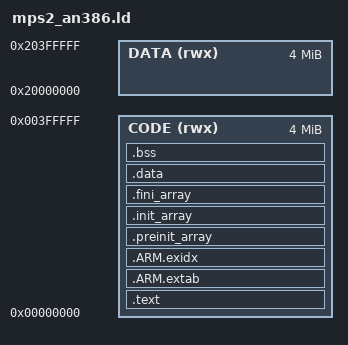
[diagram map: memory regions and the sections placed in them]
/* Linker script for tests in QEMU mps2-an386 (Cortex-M4F): everything in the 4 MB
   code RAM at 0x0, stack at the top of the data RAM. */
MEMORY { CODE (rwx) : ORIGIN = 0x00000000, LENGTH = 4M
         DATA (rwx) : ORIGIN = 0x20000000, LENGTH = 4M }
ENTRY(Reset_Handler)
SECTIONS {
  .text : { KEEP(*(.vectors)) *(.text*) *(.rodata*) KEEP(*(.init)) KEEP(*(.fini)) } > CODE
  .ARM.extab : { *(.ARM.extab* .gnu.linkonce.armextab.*) } > CODE
  .ARM.exidx : { __exidx_start = .; *(.ARM.exidx* .gnu.linkonce.armexidx.*) __exidx_end = .; } > CODE
  .preinit_array : { PROVIDE_HIDDEN(__preinit_array_start = .); KEEP(*(.preinit_array*)) PROVIDE_HIDDEN(__preinit_array_end = .); } > CODE
  .init_array : { PROVIDE_HIDDEN(__init_array_start = .); KEEP(*(SORT(.init_array.*))) KEEP(*(.init_array*)) PROVIDE_HIDDEN(__init_array_end = .); } > CODE
  .fini_array : { PROVIDE_HIDDEN(__fini_array_start = .); KEEP(*(SORT(.fini_array.*))) KEEP(*(.fini_array*)) PROVIDE_HIDDEN(__fini_array_end = .); } > CODE
  .data : { *(.data*) } > CODE
  .bss (NOLOAD) : { __bss_start__ = .; *(.bss*) *(COMMON) __bss_end__ = .; } > CODE
  end = .; _end = .; __end__ = .;
  _estack = ORIGIN(DATA) + LENGTH(DATA);
}
